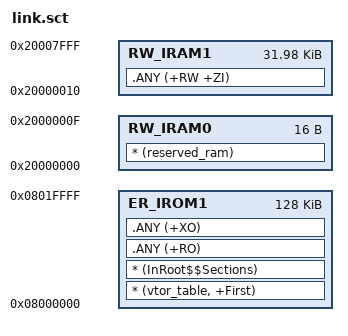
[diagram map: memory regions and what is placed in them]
; *************************************************************
; *** Scatter-Loading Description File generated by uVision ***
; *************************************************************

LR_IROM1 0x08000000 0x00020000  {    ; load region size_region
  ER_IROM1 0x08000000 0x00020000  {  ; load address = execution address
   * (vtor_table, +First)
   * (InRoot$$Sections)
   .ANY (+RO)
   .ANY (+XO)
  }

  RW_IRAM0 0x20000000 0x10  {  ; RW data
   * (reserved_ram)
  }

  RW_IRAM1 0x20000010 0x7ff0 {  ; RW data
   .ANY (+RW +ZI)
  }
}

